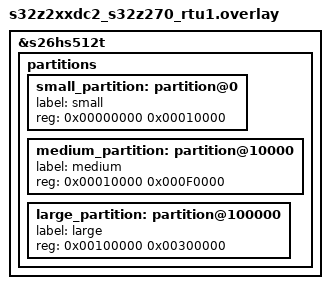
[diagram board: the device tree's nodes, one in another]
/*
 * Copyright 2024 NXP
 *
 * SPDX-License-Identifier: Apache-2.0
 */

/delete-node/ &storage_partition;

&s26hs512t {
	partitions {
		small_partition: partition@0 {
			label = "small";
			reg = <0x00000000 0x00010000>;
		};
		medium_partition: partition@10000 {
			label = "medium";
			reg = <0x00010000 0x000F0000>;
		};
		large_partition: partition@100000 {
			label = "large";
			reg = <0x00100000 0x00300000>;
		};
	};
};
